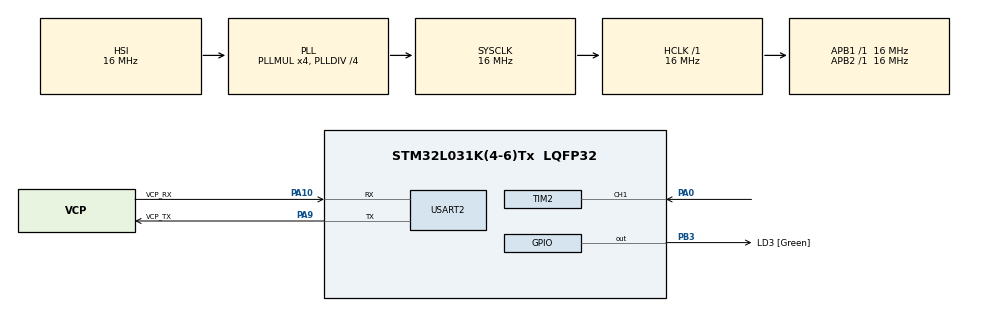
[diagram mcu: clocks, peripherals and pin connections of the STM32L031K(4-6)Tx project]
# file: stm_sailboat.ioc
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Dma.Request0=USART2_RX
Dma.Request1=USART2_TX
Dma.Request2=TIM2_CH1
Dma.TIM2_CH1.2.Direction=DMA_PERIPH_TO_MEMORY
Dma.TIM2_CH1.2.Instance=DMA1_Channel5
Dma.TIM2_CH1.2.MemDataAlignment=DMA_MDATAALIGN_HALFWORD
Dma.TIM2_CH1.2.MemInc=DMA_MINC_ENABLE
Dma.TIM2_CH1.2.Mode=DMA_CIRCULAR
Dma.TIM2_CH1.2.PeriphDataAlignment=DMA_PDATAALIGN_HALFWORD
Dma.TIM2_CH1.2.PeriphInc=DMA_PINC_DISABLE
Dma.TIM2_CH1.2.Priority=DMA_PRIORITY_LOW
Dma.USART2_RX.0.Direction=DMA_PERIPH_TO_MEMORY
Dma.USART2_RX.0.Instance=DMA1_Channel6
Dma.USART2_RX.0.MemDataAlignment=DMA_MDATAALIGN_BYTE
Dma.USART2_RX.0.MemInc=DMA_MINC_ENABLE
Dma.USART2_RX.0.Mode=DMA_CIRCULAR
Dma.USART2_RX.0.PeriphDataAlignment=DMA_PDATAALIGN_BYTE
Dma.USART2_RX.0.PeriphInc=DMA_PINC_DISABLE
Dma.USART2_RX.0.Priority=DMA_PRIORITY_LOW
Dma.USART2_TX.1.Direction=DMA_MEMORY_TO_PERIPH
Dma.USART2_TX.1.Instance=DMA1_Channel4
Dma.USART2_TX.1.MemDataAlignment=DMA_MDATAALIGN_BYTE
Dma.USART2_TX.1.MemInc=DMA_MINC_ENABLE
Dma.USART2_TX.1.Mode=DMA_NORMAL
Dma.USART2_TX.1.PeriphDataAlignment=DMA_PDATAALIGN_BYTE
Dma.USART2_TX.1.PeriphInc=DMA_PINC_DISABLE
Dma.USART2_TX.1.Priority=DMA_PRIORITY_LOW
Mcu.Family=STM32L0
Mcu.Name=STM32L031K(4-6)Tx
Mcu.Package=LQFP32
NVIC.DMA1_Channel4_5_6_7_IRQn=true\:0\:0\:false\:false\:true\:false\:true\:true
NVIC.TIM2_IRQn=true\:0\:0\:false\:false\:true\:true\:true\:true
NVIC.USART2_IRQn=true\:0\:0\:false\:false\:true\:true\:true\:true
PA0-CK_IN.Signal=S_TIM2_CH1
PA10.GPIO_Label=VCP_RX
PA10.Mode=Asynchronous
PA10.Signal=USART2_RX
PA13.GPIO_Label=TMS
PA13.Mode=Serial_Wire
PA13.Signal=SYS_SWDIO
PA14.GPIO_Label=TCK
PA14.Mode=Serial_Wire
PA14.Signal=SYS_SWCLK
PA9.GPIO_Label=VCP_TX
PA9.Mode=Asynchronous
PA9.Signal=USART2_TX
PB3.GPIO_Label=LD3 [Green]
PB3.Signal=GPIO_Output
PC14-OSC32_IN.Mode=LSE-External-Oscillator
PC14-OSC32_IN.Signal=RCC_OSC32_IN
PC15-OSC32_OUT.Mode=LSE-External-Oscillator
PC15-OSC32_OUT.Signal=RCC_OSC32_OUT
ProjectManager.HeapSize=0x200
ProjectManager.StackSize=0x400
ProjectManager.TargetToolchain=CMake
RCC.AHBFreq_Value=16000000
RCC.APB1Freq_Value=16000000
RCC.APB1TimFreq_Value=16000000
RCC.APB2Freq_Value=16000000
RCC.APB2TimFreq_Value=16000000
RCC.HCLKFreq_Value=16000000
RCC.HSE_VALUE=8000000
RCC.HSI16_VALUE=16000000
RCC.HSI48_VALUE=48000000
RCC.HSI_VALUE=16000000
RCC.MSI_VALUE=2097000
RCC.PLLDIV=RCC_PLLDIV_4
RCC.PLLMUL=RCC_PLLMUL_4
RCC.SYSCLKFreq_VALUE=16000000
RCC.SYSCLKSource=RCC_SYSCLKSOURCE_PLLCLK
RCC.VCOOutputFreq_Value=64000000
SH.S_TIM2_CH1.0=TIM2_CH1,Input_Capture1_from_TI1
TIM2.Channel-Input_Capture1_from_TI1=TIM_CHANNEL_1
TIM2.Prescaler=63
USART2.VirtualMode-Asynchronous=VM_ASYNC
board=NUCLEO-L031K6

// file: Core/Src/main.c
/* USER CODE BEGIN Header */
/**
  ******************************************************************************
  * @file           : main.c
  * @brief          : Main program body
  ******************************************************************************
  * @attention
  *
  * Copyright (c) 2026 STMicroelectronics.
  * All rights reserved.
  *
  * This software is licensed under terms that can be found in the LICENSE file
  * in the root directory of this software component.
  * If no LICENSE file comes with this software, it is provided AS-IS.
  *
  ******************************************************************************
  */
/* USER CODE END Header */
#include "main.h"

/* USER CODE BEGIN Includes */
#include "AppInterface.h"
/* USER CODE END Includes */

TIM_HandleTypeDef htim2;
DMA_HandleTypeDef hdma_tim2_ch1;

UART_HandleTypeDef huart2;
DMA_HandleTypeDef hdma_usart2_rx;
DMA_HandleTypeDef hdma_usart2_tx;

void SystemClock_Config(void);
static void MX_GPIO_Init(void);
static void MX_DMA_Init(void);
static void MX_USART2_UART_Init(void);
static void MX_TIM2_Init(void);

int main(void)
{

  /* MCU Configuration--------------------------------------------------------*/

  /* Reset of all peripherals, Initializes the Flash interface and the Systick. */
  HAL_Init();

  /* Configure the system clock */
  SystemClock_Config();

  /* USER CODE BEGIN SysInit */
// Enable debug in Sleep, Stop, and Standby modes
RCC->APB2ENR |= RCC_APB2ENR_DBGMCUEN; // Ensure DBGMCU clock is enabled
DBGMCU->CR |= DBGMCU_CR_DBG_SLEEP | DBGMCU_CR_DBG_STOP | DBGMCU_CR_DBG_STANDBY;
  /* USER CODE END SysInit */

  /* Initialize all configured peripherals */
  MX_GPIO_Init();
  MX_DMA_Init();
  MX_USART2_UART_Init();
  MX_TIM2_Init();
  /* USER CODE BEGIN 2 */
  initializeApp();
  /* USER CODE END 2 */

  /* Infinite loop */
  while (1)
  {

    /* USER CODE BEGIN 3 */
    updateApp();
  }
  /* USER CODE END 3 */
}

void SystemClock_Config(void)
{
  RCC_OscInitTypeDef RCC_OscInitStruct = {0};
  RCC_ClkInitTypeDef RCC_ClkInitStruct = {0};
  RCC_PeriphCLKInitTypeDef PeriphClkInit = {0};

  /** Configure the main internal regulator output voltage
  */
  __HAL_PWR_VOLTAGESCALING_CONFIG(PWR_REGULATOR_VOLTAGE_SCALE1);

  /** Initializes the RCC Oscillators according to the specified parameters
  * in the RCC_OscInitTypeDef structure.
  */
  RCC_OscInitStruct.OscillatorType = RCC_OSCILLATORTYPE_HSI;
  RCC_OscInitStruct.HSIState = RCC_HSI_ON;
  RCC_OscInitStruct.HSICalibrationValue = RCC_HSICALIBRATION_DEFAULT;
  RCC_OscInitStruct.PLL.PLLState = RCC_PLL_ON;
  RCC_OscInitStruct.PLL.PLLSource = RCC_PLLSOURCE_HSI;
  RCC_OscInitStruct.PLL.PLLMUL = RCC_PLLMUL_4;
  RCC_OscInitStruct.PLL.PLLDIV = RCC_PLLDIV_4;
  if (HAL_RCC_OscConfig(&RCC_OscInitStruct) != HAL_OK)
  {
    Error_Handler();
  }

  /** Initializes the CPU, AHB and APB buses clocks
  */
  RCC_ClkInitStruct.ClockType = RCC_CLOCKTYPE_HCLK|RCC_CLOCKTYPE_SYSCLK
                              |RCC_CLOCKTYPE_PCLK1|RCC_CLOCKTYPE_PCLK2;
  RCC_ClkInitStruct.SYSCLKSource = RCC_SYSCLKSOURCE_PLLCLK;
  RCC_ClkInitStruct.AHBCLKDivider = RCC_SYSCLK_DIV1;
  RCC_ClkInitStruct.APB1CLKDivider = RCC_HCLK_DIV1;
  RCC_ClkInitStruct.APB2CLKDivider = RCC_HCLK_DIV1;

  if (HAL_RCC_ClockConfig(&RCC_ClkInitStruct, FLASH_LATENCY_0) != HAL_OK)
  {
    Error_Handler();
  }
  PeriphClkInit.PeriphClockSelection = RCC_PERIPHCLK_USART2;
  PeriphClkInit.Usart2ClockSelection = RCC_USART2CLKSOURCE_PCLK1;
  if (HAL_RCCEx_PeriphCLKConfig(&PeriphClkInit) != HAL_OK)
  {
    Error_Handler();
  }
}

static void MX_TIM2_Init(void)
{

  TIM_MasterConfigTypeDef sMasterConfig = {0};
  TIM_IC_InitTypeDef sConfigIC = {0};

  htim2.Instance = TIM2;
  htim2.Init.Prescaler = 63;
  htim2.Init.CounterMode = TIM_COUNTERMODE_UP;
  htim2.Init.Period = 65535;
  htim2.Init.ClockDivision = TIM_CLOCKDIVISION_DIV1;
  htim2.Init.AutoReloadPreload = TIM_AUTORELOAD_PRELOAD_DISABLE;
  if (HAL_TIM_IC_Init(&htim2) != HAL_OK)
  {
    Error_Handler();
  }
  sMasterConfig.MasterOutputTrigger = TIM_TRGO_RESET;
  sMasterConfig.MasterSlaveMode = TIM_MASTERSLAVEMODE_DISABLE;
  if (HAL_TIMEx_MasterConfigSynchronization(&htim2, &sMasterConfig) != HAL_OK)
  {
    Error_Handler();
  }
  sConfigIC.ICPolarity = TIM_INPUTCHANNELPOLARITY_RISING;
  sConfigIC.ICSelection = TIM_ICSELECTION_DIRECTTI;
  sConfigIC.ICPrescaler = TIM_ICPSC_DIV1;
  sConfigIC.ICFilter = 0;
  if (HAL_TIM_IC_ConfigChannel(&htim2, &sConfigIC, TIM_CHANNEL_1) != HAL_OK)
  {
    Error_Handler();
  }

}

static void MX_USART2_UART_Init(void)
{

  huart2.Instance = USART2;
  huart2.Init.BaudRate = 115200;
  huart2.Init.WordLength = UART_WORDLENGTH_8B;
  huart2.Init.StopBits = UART_STOPBITS_1;
  huart2.Init.Parity = UART_PARITY_NONE;
  huart2.Init.Mode = UART_MODE_TX_RX;
  huart2.Init.HwFlowCtl = UART_HWCONTROL_NONE;
  huart2.Init.OverSampling = UART_OVERSAMPLING_16;
  huart2.Init.OneBitSampling = UART_ONE_BIT_SAMPLE_DISABLE;
  huart2.AdvancedInit.AdvFeatureInit = UART_ADVFEATURE_NO_INIT;
  if (HAL_UART_Init(&huart2) != HAL_OK)
  {
    Error_Handler();
  }

}

static void MX_DMA_Init(void)
{

  /* DMA controller clock enable */
  __HAL_RCC_DMA1_CLK_ENABLE();

  /* DMA interrupt init */
  /* DMA1_Channel4_5_6_7_IRQn interrupt configuration */
  HAL_NVIC_SetPriority(DMA1_Channel4_5_6_7_IRQn, 0, 0);
  HAL_NVIC_EnableIRQ(DMA1_Channel4_5_6_7_IRQn);

}

static void MX_GPIO_Init(void)
{
  GPIO_InitTypeDef GPIO_InitStruct = {0};

  /* GPIO Ports Clock Enable */
  __HAL_RCC_GPIOC_CLK_ENABLE();
  __HAL_RCC_GPIOA_CLK_ENABLE();
  __HAL_RCC_GPIOB_CLK_ENABLE();

  /*Configure GPIO pin Output Level */
  HAL_GPIO_WritePin(LD3_GPIO_Port, LD3_Pin, GPIO_PIN_RESET);

  /*Configure GPIO pin : LD3_Pin */
  GPIO_InitStruct.Pin = LD3_Pin;
  GPIO_InitStruct.Mode = GPIO_MODE_OUTPUT_PP;
  GPIO_InitStruct.Pull = GPIO_NOPULL;
  GPIO_InitStruct.Speed = GPIO_SPEED_FREQ_LOW;
  HAL_GPIO_Init(LD3_GPIO_Port, &GPIO_InitStruct);

}

void Error_Handler(void)
{
  __disable_irq();
  while (1)
  {
  }
}
